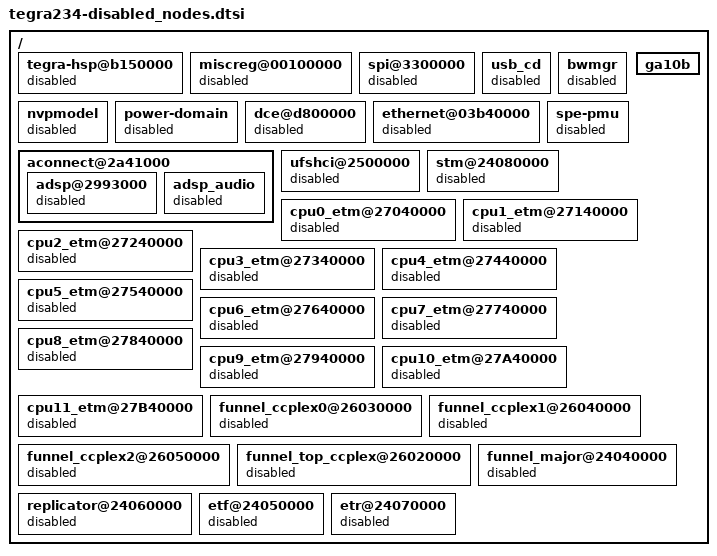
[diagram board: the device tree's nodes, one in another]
/*
 * Copyright (c) 2021, NVIDIA CORPORATION.  All rights reserved.
 *
 * This program is free software; you can redistribute it and/or modify it
 * under the terms and conditions of the GNU General Public License,
 * version 2, as published by the Free Software Foundation.
 *
 * This program is distributed in the hope it will be useful, but WITHOUT
 * ANY WARRANTY; without even the implied warranty of MERCHANTABILITY or
 * FITNESS FOR A PARTICULAR PURPOSE.  See the GNU General Public License for
 * more details.
 *
 * You should have received a copy of the GNU General Public License
 * along with this program.  If not, see <http://www.gnu.org/licenses/>.
 */

/*
 * tegra234-disabled_nodes.dts: Disabled nodes for T234
 */

/ {
        /* Disabled Nodes */

        tegra-hsp@b150000 {
                status = "disabled";
        };

        miscreg@00100000 {
                status = "disabled";
        };

        spi@3300000 {/* QSPI NOR */
                status = "disabled";
        };

        usb_cd {
                status = "disabled";
        };

        bwmgr {
                status = "disabled";
        };

        nvpmodel {
                status = "disabled";
        };

        power-domain {
                status = "disabled";
        };

        dce@d800000 {
                status = "disabled";
        };

        ethernet@03b40000 {
                status = "disabled";
        };

        spe-pmu {
                status = "disabled";
        };

	aconnect@2a41000 {
		adsp@2993000 {
			status = "disabled";
		};
		adsp_audio {
			status = "disabled";
		};
	};

	ufshci@2500000 {
		status = "disabled";
	};

	ga10b {
		status = "okay";
	};

	stm@24080000 {
		status = "disabled";
	};

	cpu0_etm@27040000 {
		status = "disabled";
	};

	cpu1_etm@27140000 {
		status = "disabled";
	};

	cpu2_etm@27240000 {
		status = "disabled";
	};

	cpu3_etm@27340000 {
		status = "disabled";
	};

	cpu4_etm@27440000 {
		status = "disabled";
	};

	cpu5_etm@27540000 {
		status = "disabled";
	};

	cpu6_etm@27640000 {
		status = "disabled";
	};

	cpu7_etm@27740000 {
		status = "disabled";
	};

	cpu8_etm@27840000 {
		status = "disabled";
	};

	cpu9_etm@27940000 {
		status = "disabled";
	};

	cpu10_etm@27A40000 {
		status = "disabled";
	};

	cpu11_etm@27B40000 {
		status = "disabled";
	};

	funnel_ccplex0@26030000 {
		status = "disabled";
	};

	funnel_ccplex1@26040000 {
		status = "disabled";
	};

	funnel_ccplex2@26050000 {
		status = "disabled";
	};

	funnel_top_ccplex@26020000 {
		status = "disabled";
	};

	funnel_major@24040000 {
		status = "disabled";
	};

	replicator@24060000 {
		status = "disabled";
	};

	etf@24050000 {
		status = "disabled";
	};

	etr@24070000 {
		status = "disabled";
	};
};
